# AT32UC3A4128S device description
Architecture: AVR32_UC3; Family: AVR UC3
Registers are 32-bit, read-write, reset 0x0 unless marked. A register's access mark holds for its fields unless they carry their own. Offsets are from the block's base; [hi:lo] are bit positions; lines under a group give offsets from that group; {n}, {i} and the like mark numbered series.

## HMATRIX — HSB Matrix
Instances: HMATRIX 0xfffe1000
{0x0+4i} mcfg[{i}] (i=0..15) access not given reset not defined
  [2:0] ULBT — Undefined Length Burst Type
    0=INFINITE; 1=SINGLE; 2=FOUR_BEAT; 3=EIGHT_BEAT; 4=SIXTEEN_BEAT
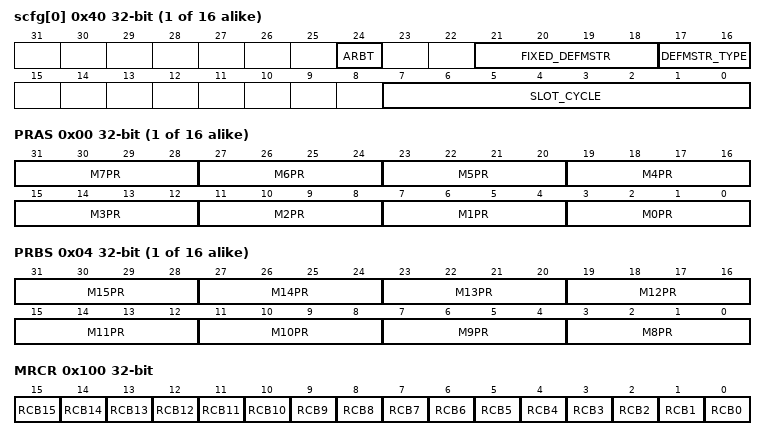
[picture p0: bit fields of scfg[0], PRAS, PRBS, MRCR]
{0x40+4i} scfg[{i}] (i=0..15) access not given reset not defined
  [24] ARBT — Arbitration Type
    0=ROUND_ROBIN; 1=FIXED_PRIORITY
  [21:18] FIXED_DEFMSTR — Fixed Index of Default Master
  [17:16] DEFMSTR_TYPE — Default Master Type
    0=NO_DEFAULT; 1=LAST_DEFAULT; 2=FIXED_DEFAULT
  [7:0] SLOT_CYCLE — Maximum Number of Allowed Cycles for a Burst
{0x80+8i} prs[{i}] (i=0..15) group
  0x00 PRAS — Priority Register A for Slave 0
    [4n+3:4n] M{n}PR (n=0..7) — Master {n} Priority
  0x04 PRBS — Priority Register B for Slave 0
    [4n-29:4n-32] M{n}PR (n=8..15) — Master {n} Priority
0x100 MRCR — Master Remap Control Register
  [n] RCB{n} (n=0..15) — Remap Command bit for Master {n}
{0x110+4i} sfr[{i}] (i=0..15) access not given
  [31:0] SFR — Special Function Register

## SDRAMC — SDRAM Controller
Instances: SDRAMC 0xfffe2000
0x00 MR — SDRAMC Mode Register
  [2:0] MODE — SDRAMC Command Mode
    0=NORMAL; 1=NOP; 2=BANKS_PRECHARGE; 3=LOAD_MODE; 4=AUTO_REFRESH; 5=EXT_LOAD_MODE; 6=POWER_DOWN
0x04 TR — SDRAMC Refresh Timer Register
  [11:0] COUNT — SDRAMC Refresh Timer Count
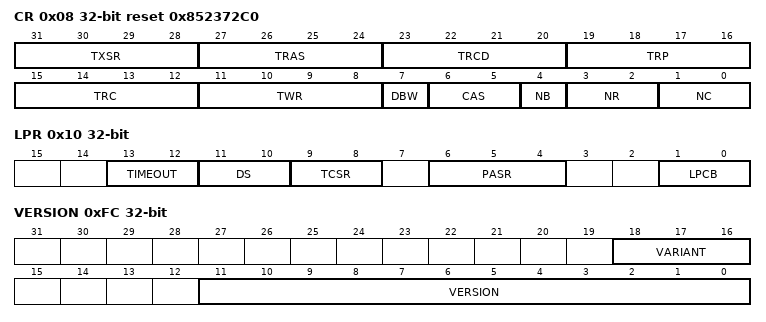
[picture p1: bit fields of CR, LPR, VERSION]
0x08 CR reset 0x852372C0 — SDRAMC Configuration Register
  [31:28] TXSR — Exit Self Refresh to Active Delay
  [27:24] TRAS — Active to Precharge Delay
  [23:20] TRCD — Row to Column Delay
  [19:16] TRP — Row Precharge Delay
  [15:12] TRC — Row Cycle Delay
  [11:8] TWR — Write Recovery Delay
  [7] DBW — Data Bus Width
    0=32_BITS; 1=16_BITS
  [6:5] CAS — CAS Latency
    1=ONE_CYCLE; 2=TWO_CYCLES; 3=THREE_CYCLES
  [4] NB — Number of Banks
    0=TWO_BANKS; 1=FOUR_BANKS
  [3:2] NR — Number of Row Bits
    0=11_ROW_BITS; 1=12_ROW_BITS; 2=13_ROW_BITS
  [1:0] NC — Number of Column Bits
    {v}={v+8}_COLUMN_BITS (v=0..3)
0x0C HSR — SDRAMC High Speed Register
  [0] DA — Decode Cycle Enable
0x10 LPR — SDRAMC Low Power Register
  [13:12] TIMEOUT — Time to define when low-power mode is enabled
    0=AFTER_END; 1=64_CYC_AFTER_END; 2=128_CYC_AFTER_END
  [11:10] DS — Drive Strength (only for low-power SDRAM)
  [9:8] TCSR — Temperature Compensated Self-Refresh (only for low-power SDRAM)
  [6:4] PASR — Partial Array Self-refresh (only for low-power SDRAM)
  [1:0] LPCB — Low-power Configuration Bits
    0=NO_LP; 1=SELF_REFRESH; 2=POWER_DOWN; 3=DEEP_POWER_DOWN
0x14 IER wo reset not defined — SDRAMC Interrupt Enable Register
  [0] RES — Refresh Error Status
0x18 IDR wo reset not defined — SDRAMC Interrupt Disable Register
  [0] RES — Refresh Error Status
0x1C IMR ro — SDRAMC Interrupt Mask Register
  [0] RES — Refresh Error Status
0x20 ISR ro — SDRAMC Interrupt Status Register
  [0] RES — Refresh Error Status
0x24 MDR — SDRAMC Memory Device Register
  [1:0] MD — Memory Device Type
    0=SDRAM; 1=LOW_POWER_SDRAM
0xEC ADDRSIZE ro — SDRAMC Addresse Size Register
0xF0 NAME1 ro — SDRAMC Name1 Register
0xF4 NAME2 ro — SDRAMC Name2 Register
0xFC VERSION ro — SDRAMC Version Register
  [18:16] VARIANT, [11:0] VERSION

## SMC — Static Memory Controller
Instances: SMC 0xfffe1c00
{0x0+0x10*i} cs[{i}] (i=0..5) group
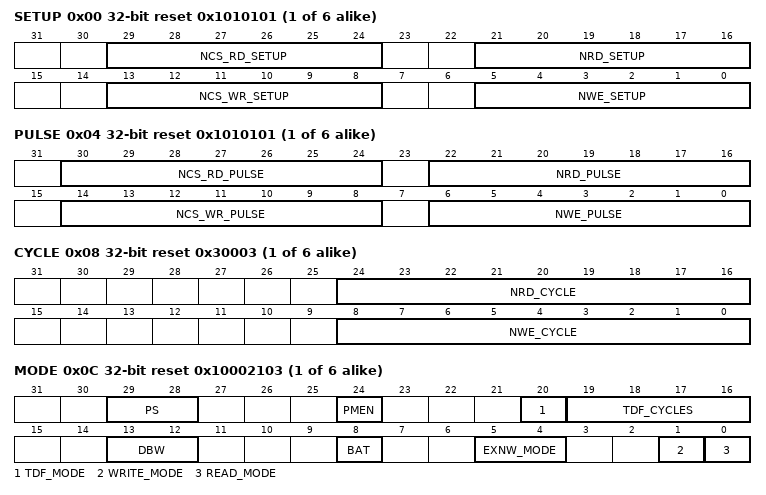
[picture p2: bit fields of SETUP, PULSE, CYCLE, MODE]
  0x00 SETUP reset 0x1010101 — SMC Setup Register
    [29:24] NCS_RD_SETUP — ncs setup length in READ access
    [21:16] NRD_SETUP — nrd setup length
    [13:8] NCS_WR_SETUP — ncs setup length in WRITE access
    [5:0] NWE_SETUP — nwe setup length
  0x04 PULSE reset 0x1010101 — SMC Pulse Register
    [30:24] NCS_RD_PULSE — ncs pulse length in READ access
    [22:16] NRD_PULSE — nrd pulse length
    [14:8] NCS_WR_PULSE — ncs pulse length in WRITE access
    [6:0] NWE_PULSE — nwe pulse length
  0x08 CYCLE reset 0x30003 — SMC Cycle Register
    [24:16] NRD_CYCLE — total read cycle length
    [8:0] NWE_CYCLE — total write cycle length
  0x0C MODE reset 0x10002103 — SMC Mode Register
    [29:28] PS — Page Size
    [24] PMEN — Page Mode enabled
    [20] TDF_MODE — TDF optimisation
    [19:16] TDF_CYCLES — Data Float Time
    [13:12] DBW — Data Bus Width
      0=8_BITS; 1=16_BITS; 2=32_BITS
    [8] BAT — Byte Access Type
      0=BYTE_SELECT; 1=BYTE_WRITE
    [5:4] EXNW_MODE — External Wait Mode
      0=DISABLED; 2=FROZEN; 3=READY
    [1] WRITE_MODE
      0=NCS_CONTROLLED; 1=NWE_CONTROLLED
    [0] READ_MODE
      0=NCS_CONTROLLED; 1=NRD_CONTROLLED
0xEC ADDRSIZE ro reset not defined — SMC Adress Size Register
0xF0 NAME1 ro reset not defined — SMC Name1 Register
0xF4 NAME2 ro reset not defined — SMC Name2 Register
0xF8 FEATURES ro reset not defined — SMC Features Register
0xFC VERSION ro reset not defined — SMC Version Register
